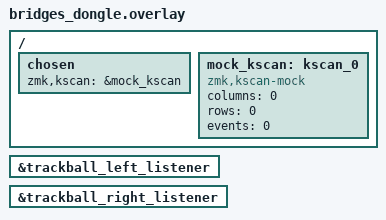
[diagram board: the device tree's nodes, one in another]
#include "bridges.dtsi"
#include "split_input_common.dtsi"

/ {
    chosen {
        zmk,kscan = &mock_kscan;
    };

    mock_kscan: kscan_0 {
        compatible = "zmk,kscan-mock";
        columns = <0>;
        rows = <0>;
        events = <0>;
    };
};

&trackball_left_listener {
    status = "okay";
};

&trackball_right_listener {
    status = "okay";
};
